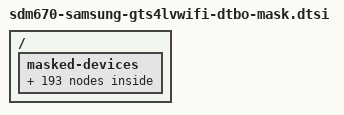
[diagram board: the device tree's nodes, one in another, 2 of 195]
// SPDX-License-Identifier: GPL-2.0-only
/*
 * Generated by gen-dtbo-mask.py from the recovery_dtbo of LineageOS 22.2's
 * recovery image. ABL refuses to boot unless that overlay applies, so its
 * labels are exported here and point at empty nodes nothing probes.
 */

/ {
	__symbols__ {
		afe = "/masked-devices/afe";
		afe_pcm_rx = "/masked-devices/afe_pcm_rx";
		afe_pcm_tx = "/masked-devices/afe_pcm_tx";
		afe_proxy_rx = "/masked-devices/afe_proxy_rx";
		afe_proxy_tx = "/masked-devices/afe_proxy_tx";
		aliases = "/masked-devices/aliases";
		apps_rsc = "/masked-devices/apps_rsc";
		aqt_intr_default = "/masked-devices/aqt_intr_default";
		aqt_rst_active = "/masked-devices/aqt_rst_active";
		aqt_rst_idle = "/masked-devices/aqt_rst_idle";
		bcl_sensor = "/masked-devices/bcl_sensor";
		cam_cci = "/masked-devices/cam_cci";
		clock_camcc = "/masked-devices/clock_camcc";
		clock_gcc = "/masked-devices/clock_gcc";
		clock_rpmh = "/masked-devices/clock_rpmh";
		compr = "/masked-devices/compr";
		compress = "/masked-devices/compress";
		dai_dp = "/masked-devices/dai_dp";
		dai_int_mi2s0 = "/masked-devices/dai_int_mi2s0";
		dai_int_mi2s1 = "/masked-devices/dai_int_mi2s1";
		dai_int_mi2s2 = "/masked-devices/dai_int_mi2s2";
		dai_int_mi2s3 = "/masked-devices/dai_int_mi2s3";
		dai_int_mi2s4 = "/masked-devices/dai_int_mi2s4";
		dai_int_mi2s5 = "/masked-devices/dai_int_mi2s5";
		dai_mi2s0 = "/masked-devices/dai_mi2s0";
		dai_mi2s1 = "/masked-devices/dai_mi2s1";
		dai_mi2s2 = "/masked-devices/dai_mi2s2";
		dai_mi2s3 = "/masked-devices/dai_mi2s3";
		dai_mi2s4 = "/masked-devices/dai_mi2s4";
		dai_pri_auxpcm = "/masked-devices/dai_pri_auxpcm";
		dai_pri_tdm_rx_0 = "/masked-devices/dai_pri_tdm_rx_0";
		dai_pri_tdm_tx_0 = "/masked-devices/dai_pri_tdm_tx_0";
		dai_quat_auxpcm = "/masked-devices/dai_quat_auxpcm";
		dai_quat_tdm_rx_0 = "/masked-devices/dai_quat_tdm_rx_0";
		dai_quat_tdm_tx_0 = "/masked-devices/dai_quat_tdm_tx_0";
		dai_quin_auxpcm = "/masked-devices/dai_quin_auxpcm";
		dai_quin_tdm_rx_0 = "/masked-devices/dai_quin_tdm_rx_0";
		dai_quin_tdm_tx_0 = "/masked-devices/dai_quin_tdm_tx_0";
		dai_sec_auxpcm = "/masked-devices/dai_sec_auxpcm";
		dai_sec_tdm_rx_0 = "/masked-devices/dai_sec_tdm_rx_0";
		dai_sec_tdm_tx_0 = "/masked-devices/dai_sec_tdm_tx_0";
		dai_tert_auxpcm = "/masked-devices/dai_tert_auxpcm";
		dai_tert_tdm_rx_0 = "/masked-devices/dai_tert_tdm_rx_0";
		dai_tert_tdm_tx_0 = "/masked-devices/dai_tert_tdm_tx_0";
		eud = "/masked-devices/eud";
		firmware = "/masked-devices/firmware";
		flash_led3_front_dis = "/masked-devices/flash_led3_front_dis";
		flash_led3_front_en = "/masked-devices/flash_led3_front_en";
		glink_spi_xprt_wdsp = "/masked-devices/glink_spi_xprt_wdsp";
		gpi_dma1 = "/masked-devices/gpi_dma1";
		hostless = "/masked-devices/hostless";
		incall_music_2_rx = "/masked-devices/incall_music_2_rx";
		incall_music_rx = "/masked-devices/incall_music_rx";
		incall_record_rx = "/masked-devices/incall_record_rx";
		incall_record_tx = "/masked-devices/incall_record_tx";
		int_codec = "/masked-devices/int_codec";
		ipa_hw = "/masked-devices/ipa_hw";
		key_vol_up_default = "/masked-devices/key_vol_up_default";
		loopback = "/masked-devices/loopback";
		lsm = "/masked-devices/lsm";
		mdss_dsi0 = "/masked-devices/mdss_dsi0";
		mdss_dsi0_pll = "/masked-devices/mdss_dsi0_pll";
		mdss_dsi1 = "/masked-devices/mdss_dsi1";
		mdss_dsi_phy0 = "/masked-devices/mdss_dsi_phy0";
		mdss_dsi_phy1 = "/masked-devices/mdss_dsi_phy1";
		mdss_mdp = "/masked-devices/mdss_mdp";
		nfc_clk_default = "/masked-devices/nfc_clk_default";
		nfc_enable_active = "/masked-devices/nfc_enable_active";
		nfc_enable_suspend = "/masked-devices/nfc_enable_suspend";
		nfc_int_active = "/masked-devices/nfc_int_active";
		nfc_int_suspend = "/masked-devices/nfc_int_suspend";
		pcm0 = "/masked-devices/pcm0";
		pcm1 = "/masked-devices/pcm1";
		pcm2 = "/masked-devices/pcm2";
		pcm_noirq = "/masked-devices/pcm_noirq";
		pdc = "/masked-devices/pdc";
		pil_adsp_mem = "/masked-devices/pil_adsp_mem";
		pil_gpu_mem = "/masked-devices/pil_gpu_mem";
		pil_ipa_fw_mem = "/masked-devices/pil_ipa_fw_mem";
		pil_ipa_gsi_mem = "/masked-devices/pil_ipa_gsi_mem";
		pm660_0 = "/masked-devices/pm660_0";
		pm660_1 = "/masked-devices/pm660_1";
		pm660_div_clk = "/masked-devices/pm660_div_clk";
		pm660_l1 = "/masked-devices/pm660_l1";
		pm660_l10 = "/masked-devices/pm660_l10";
		pm660_l14 = "/masked-devices/pm660_l14";
		pm660_l8 = "/masked-devices/pm660_l8";
		pm660_misc = "/masked-devices/pm660_misc";
		pm660_pdphy = "/masked-devices/pm660_pdphy";
		pm660_revid = "/masked-devices/pm660_revid";
		pm660_s4 = "/masked-devices/pm660_s4";
		pm660_vadc = "/masked-devices/pm660_vadc";
		pm660l_3 = "/masked-devices/pm660l_3";
		pm660l_bob = "/masked-devices/pm660l_bob";
		pm660l_gpios = "/masked-devices/pm660l_gpios";
		pm660l_l1 = "/masked-devices/pm660l_l1";
		pm660l_l2 = "/masked-devices/pm660l_l2";
		pm660l_l3 = "/masked-devices/pm660l_l3";
		pm660l_l4 = "/masked-devices/pm660l_l4";
		pm660l_l5 = "/masked-devices/pm660l_l5";
		pm660l_l6 = "/masked-devices/pm660l_l6";
		pm660l_l7 = "/masked-devices/pm660l_l7";
		pm660l_l8 = "/masked-devices/pm660l_l8";
		pm660l_pbs = "/masked-devices/pm660l_pbs";
		pm660l_revid = "/masked-devices/pm660l_revid";
		pm660l_switch1 = "/masked-devices/pm660l_switch1";
		proxy_rx = "/masked-devices/proxy_rx";
		proxy_tx = "/masked-devices/proxy_tx";
		qupv3_1 = "/masked-devices/qupv3_1";
		qupv3_se0_i2c = "/masked-devices/qupv3_se0_i2c";
		qupv3_se10_i2c = "/masked-devices/qupv3_se10_i2c";
		qupv3_se12_2uart = "/masked-devices/qupv3_se12_2uart";
		qupv3_se12_2uart_pins = "/masked-devices/qupv3_se12_2uart_pins";
		qupv3_se2_i2c = "/masked-devices/qupv3_se2_i2c";
		qupv3_se3_i2c = "/masked-devices/qupv3_se3_i2c";
		qupv3_se3_i2c_active = "/masked-devices/qupv3_se3_i2c_active";
		qupv3_se3_i2c_pins = "/masked-devices/qupv3_se3_i2c_pins";
		qupv3_se6_4uart = "/masked-devices/qupv3_se6_4uart";
		qupv3_se7_i2c = "/masked-devices/qupv3_se7_i2c";
		qupv3_se8_spi = "/masked-devices/qupv3_se8_spi";
		qupv3_se9_2uart = "/masked-devices/qupv3_se9_2uart";
		qupv3_se9_i2c = "/masked-devices/qupv3_se9_i2c";
		qusb_phy0 = "/masked-devices/qusb_phy0";
		removed_region = "/masked-devices/removed_region";
		reserved_memory = "/masked-devices/reserved_memory";
		routing = "/masked-devices/routing";
		sb_7_rx = "/masked-devices/sb_7_rx";
		sb_7_tx = "/masked-devices/sb_7_tx";
		sb_8_rx = "/masked-devices/sb_8_rx";
		sb_8_tx = "/masked-devices/sb_8_tx";
		sdc1_clk_off = "/masked-devices/sdc1_clk_off";
		sdc1_clk_on = "/masked-devices/sdc1_clk_on";
		sdc1_cmd_off = "/masked-devices/sdc1_cmd_off";
		sdc1_cmd_on = "/masked-devices/sdc1_cmd_on";
		sdc1_rclk_off = "/masked-devices/sdc1_rclk_off";
		sdc1_rclk_on = "/masked-devices/sdc1_rclk_on";
		sdc2_clk_off = "/masked-devices/sdc2_clk_off";
		sdc2_clk_on = "/masked-devices/sdc2_clk_on";
		sdc2_cmd_off = "/masked-devices/sdc2_cmd_off";
		sdc2_cmd_on = "/masked-devices/sdc2_cmd_on";
		sdc2_data_off = "/masked-devices/sdc2_data_off";
		sdc2_data_on = "/masked-devices/sdc2_data_on";
		sde_dp = "/masked-devices/sde_dp";
		sde_dp_aux_active = "/masked-devices/sde_dp_aux_active";
		sde_dp_aux_suspend = "/masked-devices/sde_dp_aux_suspend";
		sde_dp_usbplug_cc_active = "/masked-devices/sde_dp_usbplug_cc_active";
		sde_dp_usbplug_cc_suspend = "/masked-devices/sde_dp_usbplug_cc_suspend";
		sde_rscc = "/masked-devices/sde_rscc";
		sdhc_1 = "/masked-devices/sdhc_1";
		sdhc_2 = "/masked-devices/sdhc_2";
		sdw_clk_active = "/masked-devices/sdw_clk_active";
		sdw_clk_sleep = "/masked-devices/sdw_clk_sleep";
		sdw_data_active = "/masked-devices/sdw_data_active";
		sdw_data_sleep = "/masked-devices/sdw_data_sleep";
		secure_display_memory = "/masked-devices/secure_display_memory";
		slim_aud = "/masked-devices/slim_aud";
		smb_shutdown_default = "/masked-devices/smb_shutdown_default";
		soc = "/masked-devices/soc";
		spkr_1_sd_n_active = "/masked-devices/spkr_1_sd_n_active";
		spkr_1_sd_n_sleep = "/masked-devices/spkr_1_sd_n_sleep";
		spkr_2_sd_n_active = "/masked-devices/spkr_2_sd_n_active";
		spkr_2_sd_n_sleep = "/masked-devices/spkr_2_sd_n_sleep";
		spmi_bus = "/masked-devices/spmi_bus";
		stub_codec = "/masked-devices/stub_codec";
		tasha_mclk_default = "/masked-devices/tasha_mclk_default";
		tasha_snd = "/masked-devices/tasha_snd";
		tasha_spkr_1_sd_n_active = "/masked-devices/tasha_spkr_1_sd_n_active";
		tasha_spkr_1_sd_n_sleep = "/masked-devices/tasha_spkr_1_sd_n_sleep";
		tasha_spkr_2_sd_n_active = "/masked-devices/tasha_spkr_2_sd_n_active";
		tasha_spkr_2_sd_n_sleep = "/masked-devices/tasha_spkr_2_sd_n_sleep";
		tavil_snd = "/masked-devices/tavil_snd";
		ter_i2s_data0_active = "/masked-devices/ter_i2s_data0_active";
		ter_i2s_data0_sleep = "/masked-devices/ter_i2s_data0_sleep";
		ter_i2s_data1_active = "/masked-devices/ter_i2s_data1_active";
		ter_i2s_data1_sleep = "/masked-devices/ter_i2s_data1_sleep";
		ter_i2s_sck_active = "/masked-devices/ter_i2s_sck_active";
		ter_i2s_sck_sleep = "/masked-devices/ter_i2s_sck_sleep";
		thermal_zones = "/masked-devices/thermal_zones";
		titan_top_gdsc = "/masked-devices/titan_top_gdsc";
		tlmm = "/masked-devices/tlmm";
		ufs_phy_gdsc = "/masked-devices/ufs_phy_gdsc";
		ufshc_mem = "/masked-devices/ufshc_mem";
		ufsphy_mem = "/masked-devices/ufsphy_mem";
		usb0 = "/masked-devices/usb0";
		usb_audio_rx = "/masked-devices/usb_audio_rx";
		usb_audio_tx = "/masked-devices/usb_audio_tx";
		vendor = "/masked-devices/vendor";
		voice = "/masked-devices/voice";
		voip = "/masked-devices/voip";
		wcd_intr_default = "/masked-devices/wcd_intr_default";
		wcd_usbc_analog_en1_active = "/masked-devices/wcd_usbc_analog_en1_active";
		wcd_usbc_analog_en1_idle = "/masked-devices/wcd_usbc_analog_en1_idle";
	};

	masked-devices {
		masked = <&_masked_afe>,
			 <&_masked_afe_pcm_rx>,
			 <&_masked_afe_pcm_tx>,
			 <&_masked_afe_proxy_rx>,
			 <&_masked_afe_proxy_tx>,
			 <&_masked_aliases>,
			 <&_masked_apps_rsc>,
			 <&_masked_aqt_intr_default>,
			 <&_masked_aqt_rst_active>,
			 <&_masked_aqt_rst_idle>,
			 <&_masked_bcl_sensor>,
			 <&_masked_cam_cci>,
			 <&_masked_clock_camcc>,
			 <&_masked_clock_gcc>,
			 <&_masked_clock_rpmh>,
			 <&_masked_compr>,
			 <&_masked_compress>,
			 <&_masked_dai_dp>,
			 <&_masked_dai_int_mi2s0>,
			 <&_masked_dai_int_mi2s1>,
			 <&_masked_dai_int_mi2s2>,
			 <&_masked_dai_int_mi2s3>,
			 <&_masked_dai_int_mi2s4>,
			 <&_masked_dai_int_mi2s5>,
			 <&_masked_dai_mi2s0>,
			 <&_masked_dai_mi2s1>,
			 <&_masked_dai_mi2s2>,
			 <&_masked_dai_mi2s3>,
			 <&_masked_dai_mi2s4>,
			 <&_masked_dai_pri_auxpcm>,
			 <&_masked_dai_pri_tdm_rx_0>,
			 <&_masked_dai_pri_tdm_tx_0>,
			 <&_masked_dai_quat_auxpcm>,
			 <&_masked_dai_quat_tdm_rx_0>,
			 <&_masked_dai_quat_tdm_tx_0>,
			 <&_masked_dai_quin_auxpcm>,
			 <&_masked_dai_quin_tdm_rx_0>,
			 <&_masked_dai_quin_tdm_tx_0>,
			 <&_masked_dai_sec_auxpcm>,
			 <&_masked_dai_sec_tdm_rx_0>,
			 <&_masked_dai_sec_tdm_tx_0>,
			 <&_masked_dai_tert_auxpcm>,
			 <&_masked_dai_tert_tdm_rx_0>,
			 <&_masked_dai_tert_tdm_tx_0>,
			 <&_masked_eud>,
			 <&_masked_firmware>,
			 <&_masked_flash_led3_front_dis>,
			 <&_masked_flash_led3_front_en>,
			 <&_masked_glink_spi_xprt_wdsp>,
			 <&_masked_gpi_dma1>,
			 <&_masked_hostless>,
			 <&_masked_incall_music_2_rx>,
			 <&_masked_incall_music_rx>,
			 <&_masked_incall_record_rx>,
			 <&_masked_incall_record_tx>,
			 <&_masked_int_codec>,
			 <&_masked_ipa_hw>,
			 <&_masked_key_vol_up_default>,
			 <&_masked_loopback>,
			 <&_masked_lsm>,
			 <&_masked_mdss_dsi0>,
			 <&_masked_mdss_dsi0_pll>,
			 <&_masked_mdss_dsi1>,
			 <&_masked_mdss_dsi_phy0>,
			 <&_masked_mdss_dsi_phy1>,
			 <&_masked_mdss_mdp>,
			 <&_masked_nfc_clk_default>,
			 <&_masked_nfc_enable_active>,
			 <&_masked_nfc_enable_suspend>,
			 <&_masked_nfc_int_active>,
			 <&_masked_nfc_int_suspend>,
			 <&_masked_pcm0>,
			 <&_masked_pcm1>,
			 <&_masked_pcm2>,
			 <&_masked_pcm_noirq>,
			 <&_masked_pdc>,
			 <&_masked_pil_adsp_mem>,
			 <&_masked_pil_gpu_mem>,
			 <&_masked_pil_ipa_fw_mem>,
			 <&_masked_pil_ipa_gsi_mem>,
			 <&_masked_pm660_0>,
			 <&_masked_pm660_1>,
			 <&_masked_pm660_div_clk>,
			 <&_masked_pm660_l1>,
			 <&_masked_pm660_l10>,
			 <&_masked_pm660_l14>,
			 <&_masked_pm660_l8>,
			 <&_masked_pm660_misc>,
			 <&_masked_pm660_pdphy>,
			 <&_masked_pm660_revid>,
			 <&_masked_pm660_s4>,
			 <&_masked_pm660_vadc>,
			 <&_masked_pm660l_3>,
			 <&_masked_pm660l_bob>,
			 <&_masked_pm660l_gpios>,
			 <&_masked_pm660l_l1>,
			 <&_masked_pm660l_l2>,
			 <&_masked_pm660l_l3>,
			 <&_masked_pm660l_l4>,
			 <&_masked_pm660l_l5>,
			 <&_masked_pm660l_l6>,
			 <&_masked_pm660l_l7>,
			 <&_masked_pm660l_l8>,
			 <&_masked_pm660l_pbs>,
			 <&_masked_pm660l_revid>,
			 <&_masked_pm660l_switch1>,
			 <&_masked_proxy_rx>,
			 <&_masked_proxy_tx>,
			 <&_masked_qupv3_1>,
			 <&_masked_qupv3_se0_i2c>,
			 <&_masked_qupv3_se10_i2c>,
			 <&_masked_qupv3_se12_2uart>,
			 <&_masked_qupv3_se12_2uart_pins>,
			 <&_masked_qupv3_se2_i2c>,
			 <&_masked_qupv3_se3_i2c>,
			 <&_masked_qupv3_se3_i2c_active>,
			 <&_masked_qupv3_se3_i2c_pins>,
			 <&_masked_qupv3_se6_4uart>,
			 <&_masked_qupv3_se7_i2c>,
			 <&_masked_qupv3_se8_spi>,
			 <&_masked_qupv3_se9_2uart>,
			 <&_masked_qupv3_se9_i2c>,
			 <&_masked_qusb_phy0>,
			 <&_masked_removed_region>,
			 <&_masked_reserved_memory>,
			 <&_masked_routing>,
			 <&_masked_sb_7_rx>,
			 <&_masked_sb_7_tx>,
			 <&_masked_sb_8_rx>,
			 <&_masked_sb_8_tx>,
			 <&_masked_sdc1_clk_off>,
			 <&_masked_sdc1_clk_on>,
			 <&_masked_sdc1_cmd_off>,
			 <&_masked_sdc1_cmd_on>,
			 <&_masked_sdc1_rclk_off>,
			 <&_masked_sdc1_rclk_on>,
			 <&_masked_sdc2_clk_off>,
			 <&_masked_sdc2_clk_on>,
			 <&_masked_sdc2_cmd_off>,
			 <&_masked_sdc2_cmd_on>,
			 <&_masked_sdc2_data_off>,
			 <&_masked_sdc2_data_on>,
			 <&_masked_sde_dp>,
			 <&_masked_sde_dp_aux_active>,
			 <&_masked_sde_dp_aux_suspend>,
			 <&_masked_sde_dp_usbplug_cc_active>,
			 <&_masked_sde_dp_usbplug_cc_suspend>,
			 <&_masked_sde_rscc>,
			 <&_masked_sdhc_1>,
			 <&_masked_sdhc_2>,
			 <&_masked_sdw_clk_active>,
			 <&_masked_sdw_clk_sleep>,
			 <&_masked_sdw_data_active>,
			 <&_masked_sdw_data_sleep>,
			 <&_masked_secure_display_memory>,
			 <&_masked_slim_aud>,
			 <&_masked_smb_shutdown_default>,
			 <&_masked_soc>,
			 <&_masked_spkr_1_sd_n_active>,
			 <&_masked_spkr_1_sd_n_sleep>,
			 <&_masked_spkr_2_sd_n_active>,
			 <&_masked_spkr_2_sd_n_sleep>,
			 <&_masked_spmi_bus>,
			 <&_masked_stub_codec>,
			 <&_masked_tasha_mclk_default>,
			 <&_masked_tasha_snd>,
			 <&_masked_tasha_spkr_1_sd_n_active>,
			 <&_masked_tasha_spkr_1_sd_n_sleep>,
			 <&_masked_tasha_spkr_2_sd_n_active>,
			 <&_masked_tasha_spkr_2_sd_n_sleep>,
			 <&_masked_tavil_snd>,
			 <&_masked_ter_i2s_data0_active>,
			 <&_masked_ter_i2s_data0_sleep>,
			 <&_masked_ter_i2s_data1_active>,
			 <&_masked_ter_i2s_data1_sleep>,
			 <&_masked_ter_i2s_sck_active>,
			 <&_masked_ter_i2s_sck_sleep>,
			 <&_masked_thermal_zones>,
			 <&_masked_titan_top_gdsc>,
			 <&_masked_tlmm>,
			 <&_masked_ufs_phy_gdsc>,
			 <&_masked_ufshc_mem>,
			 <&_masked_ufsphy_mem>,
			 <&_masked_usb0>,
			 <&_masked_usb_audio_rx>,
			 <&_masked_usb_audio_tx>,
			 <&_masked_vendor>,
			 <&_masked_voice>,
			 <&_masked_voip>,
			 <&_masked_wcd_intr_default>,
			 <&_masked_wcd_usbc_analog_en1_active>,
			 <&_masked_wcd_usbc_analog_en1_idle>;

		_masked_afe: afe {};
		_masked_afe_pcm_rx: afe_pcm_rx {};
		_masked_afe_pcm_tx: afe_pcm_tx {};
		_masked_afe_proxy_rx: afe_proxy_rx {};
		_masked_afe_proxy_tx: afe_proxy_tx {};
		_masked_aliases: aliases {};
		_masked_apps_rsc: apps_rsc {};
		_masked_aqt_intr_default: aqt_intr_default {};
		_masked_aqt_rst_active: aqt_rst_active {};
		_masked_aqt_rst_idle: aqt_rst_idle {};
		_masked_bcl_sensor: bcl_sensor {};
		_masked_cam_cci: cam_cci {};
		_masked_clock_camcc: clock_camcc {};
		_masked_clock_gcc: clock_gcc {};
		_masked_clock_rpmh: clock_rpmh {};
		_masked_compr: compr {};
		_masked_compress: compress {};
		_masked_dai_dp: dai_dp {};
		_masked_dai_int_mi2s0: dai_int_mi2s0 {};
		_masked_dai_int_mi2s1: dai_int_mi2s1 {};
		_masked_dai_int_mi2s2: dai_int_mi2s2 {};
		_masked_dai_int_mi2s3: dai_int_mi2s3 {};
		_masked_dai_int_mi2s4: dai_int_mi2s4 {};
		_masked_dai_int_mi2s5: dai_int_mi2s5 {};
		_masked_dai_mi2s0: dai_mi2s0 {};
		_masked_dai_mi2s1: dai_mi2s1 {};
		_masked_dai_mi2s2: dai_mi2s2 {};
		_masked_dai_mi2s3: dai_mi2s3 {};
		_masked_dai_mi2s4: dai_mi2s4 {};
		_masked_dai_pri_auxpcm: dai_pri_auxpcm {};
		_masked_dai_pri_tdm_rx_0: dai_pri_tdm_rx_0 {};
		_masked_dai_pri_tdm_tx_0: dai_pri_tdm_tx_0 {};
		_masked_dai_quat_auxpcm: dai_quat_auxpcm {};
		_masked_dai_quat_tdm_rx_0: dai_quat_tdm_rx_0 {};
		_masked_dai_quat_tdm_tx_0: dai_quat_tdm_tx_0 {};
		_masked_dai_quin_auxpcm: dai_quin_auxpcm {};
		_masked_dai_quin_tdm_rx_0: dai_quin_tdm_rx_0 {};
		_masked_dai_quin_tdm_tx_0: dai_quin_tdm_tx_0 {};
		_masked_dai_sec_auxpcm: dai_sec_auxpcm {};
		_masked_dai_sec_tdm_rx_0: dai_sec_tdm_rx_0 {};
		_masked_dai_sec_tdm_tx_0: dai_sec_tdm_tx_0 {};
		_masked_dai_tert_auxpcm: dai_tert_auxpcm {};
		_masked_dai_tert_tdm_rx_0: dai_tert_tdm_rx_0 {};
		_masked_dai_tert_tdm_tx_0: dai_tert_tdm_tx_0 {};
		_masked_eud: eud {};
		_masked_firmware: firmware {};
		_masked_flash_led3_front_dis: flash_led3_front_dis {};
		_masked_flash_led3_front_en: flash_led3_front_en {};
		_masked_glink_spi_xprt_wdsp: glink_spi_xprt_wdsp {};
		_masked_gpi_dma1: gpi_dma1 {};
		_masked_hostless: hostless {};
		_masked_incall_music_2_rx: incall_music_2_rx {};
		_masked_incall_music_rx: incall_music_rx {};
		_masked_incall_record_rx: incall_record_rx {};
		_masked_incall_record_tx: incall_record_tx {};
		_masked_int_codec: int_codec {};
		_masked_ipa_hw: ipa_hw {};
		_masked_key_vol_up_default: key_vol_up_default {};
		_masked_loopback: loopback {};
		_masked_lsm: lsm {};
		_masked_mdss_dsi0: mdss_dsi0 {};
		_masked_mdss_dsi0_pll: mdss_dsi0_pll {};
		_masked_mdss_dsi1: mdss_dsi1 {};
		_masked_mdss_dsi_phy0: mdss_dsi_phy0 {};
		_masked_mdss_dsi_phy1: mdss_dsi_phy1 {};
		_masked_mdss_mdp: mdss_mdp {};
		_masked_nfc_clk_default: nfc_clk_default {};
		_masked_nfc_enable_active: nfc_enable_active {};
		_masked_nfc_enable_suspend: nfc_enable_suspend {};
		_masked_nfc_int_active: nfc_int_active {};
		_masked_nfc_int_suspend: nfc_int_suspend {};
		_masked_pcm0: pcm0 {};
		_masked_pcm1: pcm1 {};
		_masked_pcm2: pcm2 {};
		_masked_pcm_noirq: pcm_noirq {};
		_masked_pdc: pdc {};
		_masked_pil_adsp_mem: pil_adsp_mem {};
		_masked_pil_gpu_mem: pil_gpu_mem {};
		_masked_pil_ipa_fw_mem: pil_ipa_fw_mem {};
		_masked_pil_ipa_gsi_mem: pil_ipa_gsi_mem {};
		_masked_pm660_0: pm660_0 {};
		_masked_pm660_1: pm660_1 {};
		_masked_pm660_div_clk: pm660_div_clk {};
		_masked_pm660_l1: pm660_l1 {};
		_masked_pm660_l10: pm660_l10 {};
		_masked_pm660_l14: pm660_l14 {};
		_masked_pm660_l8: pm660_l8 {};
		_masked_pm660_misc: pm660_misc {};
		_masked_pm660_pdphy: pm660_pdphy {};
		_masked_pm660_revid: pm660_revid {};
		_masked_pm660_s4: pm660_s4 {};
		_masked_pm660_vadc: pm660_vadc {};
		_masked_pm660l_3: pm660l_3 {};
		_masked_pm660l_bob: pm660l_bob {};
		_masked_pm660l_gpios: pm660l_gpios {};
		_masked_pm660l_l1: pm660l_l1 {};
		_masked_pm660l_l2: pm660l_l2 {};
		_masked_pm660l_l3: pm660l_l3 {};
		_masked_pm660l_l4: pm660l_l4 {};
		_masked_pm660l_l5: pm660l_l5 {};
		_masked_pm660l_l6: pm660l_l6 {};
		_masked_pm660l_l7: pm660l_l7 {};
		_masked_pm660l_l8: pm660l_l8 {};
		_masked_pm660l_pbs: pm660l_pbs {};
		_masked_pm660l_revid: pm660l_revid {};
		_masked_pm660l_switch1: pm660l_switch1 {};
		_masked_proxy_rx: proxy_rx {};
		_masked_proxy_tx: proxy_tx {};
		_masked_qupv3_1: qupv3_1 {};
		_masked_qupv3_se0_i2c: qupv3_se0_i2c {};
		_masked_qupv3_se10_i2c: qupv3_se10_i2c {};
		_masked_qupv3_se12_2uart: qupv3_se12_2uart {};
		_masked_qupv3_se12_2uart_pins: qupv3_se12_2uart_pins {};
		_masked_qupv3_se2_i2c: qupv3_se2_i2c {};
		_masked_qupv3_se3_i2c: qupv3_se3_i2c {};
		_masked_qupv3_se3_i2c_active: qupv3_se3_i2c_active {};
		_masked_qupv3_se3_i2c_pins: qupv3_se3_i2c_pins {};
		_masked_qupv3_se6_4uart: qupv3_se6_4uart {};
		_masked_qupv3_se7_i2c: qupv3_se7_i2c {};
		_masked_qupv3_se8_spi: qupv3_se8_spi {};
		_masked_qupv3_se9_2uart: qupv3_se9_2uart {};
		_masked_qupv3_se9_i2c: qupv3_se9_i2c {};
		_masked_qusb_phy0: qusb_phy0 {};
		_masked_removed_region: removed_region {};
		_masked_reserved_memory: reserved_memory {};
		_masked_routing: routing {};
		_masked_sb_7_rx: sb_7_rx {};
		_masked_sb_7_tx: sb_7_tx {};
		_masked_sb_8_rx: sb_8_rx {};
		_masked_sb_8_tx: sb_8_tx {};
		_masked_sdc1_clk_off: sdc1_clk_off {};
		_masked_sdc1_clk_on: sdc1_clk_on {};
		_masked_sdc1_cmd_off: sdc1_cmd_off {};
		_masked_sdc1_cmd_on: sdc1_cmd_on {};
		_masked_sdc1_rclk_off: sdc1_rclk_off {};
		_masked_sdc1_rclk_on: sdc1_rclk_on {};
		_masked_sdc2_clk_off: sdc2_clk_off {};
		_masked_sdc2_clk_on: sdc2_clk_on {};
		_masked_sdc2_cmd_off: sdc2_cmd_off {};
		_masked_sdc2_cmd_on: sdc2_cmd_on {};
		_masked_sdc2_data_off: sdc2_data_off {};
		_masked_sdc2_data_on: sdc2_data_on {};
		_masked_sde_dp: sde_dp {};
		_masked_sde_dp_aux_active: sde_dp_aux_active {};
		_masked_sde_dp_aux_suspend: sde_dp_aux_suspend {};
		_masked_sde_dp_usbplug_cc_active: sde_dp_usbplug_cc_active {};
		_masked_sde_dp_usbplug_cc_suspend: sde_dp_usbplug_cc_suspend {};
		_masked_sde_rscc: sde_rscc {};
		_masked_sdhc_1: sdhc_1 {};
		_masked_sdhc_2: sdhc_2 {};
		_masked_sdw_clk_active: sdw_clk_active {};
		_masked_sdw_clk_sleep: sdw_clk_sleep {};
		_masked_sdw_data_active: sdw_data_active {};
		_masked_sdw_data_sleep: sdw_data_sleep {};
		_masked_secure_display_memory: secure_display_memory {};
		_masked_slim_aud: slim_aud {};
		_masked_smb_shutdown_default: smb_shutdown_default {};
		_masked_soc: soc {};
		_masked_spkr_1_sd_n_active: spkr_1_sd_n_active {};
		_masked_spkr_1_sd_n_sleep: spkr_1_sd_n_sleep {};
		_masked_spkr_2_sd_n_active: spkr_2_sd_n_active {};
		_masked_spkr_2_sd_n_sleep: spkr_2_sd_n_sleep {};
		_masked_spmi_bus: spmi_bus {};
		_masked_stub_codec: stub_codec {};
		_masked_tasha_mclk_default: tasha_mclk_default {};
		_masked_tasha_snd: tasha_snd {};
		_masked_tasha_spkr_1_sd_n_active: tasha_spkr_1_sd_n_active {};
		_masked_tasha_spkr_1_sd_n_sleep: tasha_spkr_1_sd_n_sleep {};
		_masked_tasha_spkr_2_sd_n_active: tasha_spkr_2_sd_n_active {};
		_masked_tasha_spkr_2_sd_n_sleep: tasha_spkr_2_sd_n_sleep {};
		_masked_tavil_snd: tavil_snd {};
		_masked_ter_i2s_data0_active: ter_i2s_data0_active {};
		_masked_ter_i2s_data0_sleep: ter_i2s_data0_sleep {};
		_masked_ter_i2s_data1_active: ter_i2s_data1_active {};
		_masked_ter_i2s_data1_sleep: ter_i2s_data1_sleep {};
		_masked_ter_i2s_sck_active: ter_i2s_sck_active {};
		_masked_ter_i2s_sck_sleep: ter_i2s_sck_sleep {};
		_masked_thermal_zones: thermal_zones {};
		_masked_titan_top_gdsc: titan_top_gdsc {};
		_masked_tlmm: tlmm {};
		_masked_ufs_phy_gdsc: ufs_phy_gdsc {};
		_masked_ufshc_mem: ufshc_mem {};
		_masked_ufsphy_mem: ufsphy_mem {};
		_masked_usb0: usb0 {};
		_masked_usb_audio_rx: usb_audio_rx {};
		_masked_usb_audio_tx: usb_audio_tx {};
		_masked_vendor: vendor {};
		_masked_voice: voice {};
		_masked_voip: voip {};
		_masked_wcd_intr_default: wcd_intr_default {};
		_masked_wcd_usbc_analog_en1_active: wcd_usbc_analog_en1_active {};
		_masked_wcd_usbc_analog_en1_idle: wcd_usbc_analog_en1_idle {};
	};
};

/* The overlay adds a second ramoops at our ramoops' address; keep it off. */
&_masked_reserved_memory {
	ramoops@A1300000 {
		status = "disabled";
	};
};
